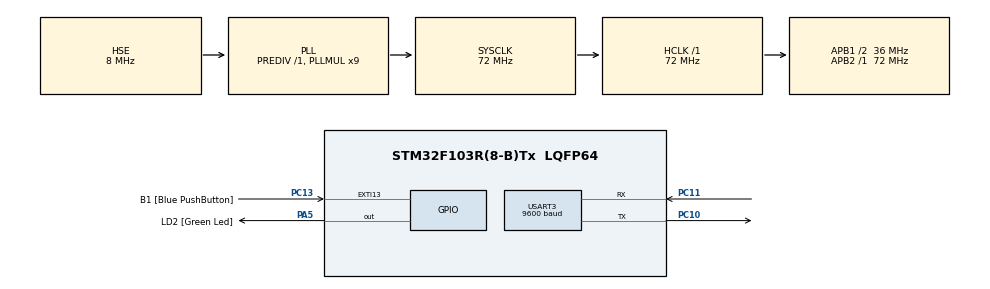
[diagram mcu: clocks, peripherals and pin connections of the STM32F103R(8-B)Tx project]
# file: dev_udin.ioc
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Dma.Request0=USART3_RX
Dma.Request1=USART3_TX
Dma.USART3_RX.0.Direction=DMA_PERIPH_TO_MEMORY
Dma.USART3_RX.0.Instance=DMA1_Channel3
Dma.USART3_RX.0.MemDataAlignment=DMA_MDATAALIGN_BYTE
Dma.USART3_RX.0.MemInc=DMA_MINC_ENABLE
Dma.USART3_RX.0.Mode=DMA_NORMAL
Dma.USART3_RX.0.PeriphDataAlignment=DMA_PDATAALIGN_BYTE
Dma.USART3_RX.0.PeriphInc=DMA_PINC_DISABLE
Dma.USART3_RX.0.Priority=DMA_PRIORITY_LOW
Dma.USART3_TX.1.Direction=DMA_MEMORY_TO_PERIPH
Dma.USART3_TX.1.Instance=DMA1_Channel2
Dma.USART3_TX.1.MemDataAlignment=DMA_MDATAALIGN_BYTE
Dma.USART3_TX.1.MemInc=DMA_MINC_ENABLE
Dma.USART3_TX.1.Mode=DMA_NORMAL
Dma.USART3_TX.1.PeriphDataAlignment=DMA_PDATAALIGN_BYTE
Dma.USART3_TX.1.PeriphInc=DMA_PINC_DISABLE
Dma.USART3_TX.1.Priority=DMA_PRIORITY_LOW
FREERTOS.Tasks01=defaultTask,0,128,StartDefaultTask,Default,NULL
Mcu.Family=STM32F1
Mcu.Name=STM32F103R(8-B)Tx
Mcu.Package=LQFP64
NVIC.DMA1_Channel2_IRQn=true\:5\:0\:false\:false\:true\:true
NVIC.DMA1_Channel3_IRQn=true\:5\:0\:false\:false\:true\:true
NVIC.EXTI15_10_IRQn=true\:5\:0\:false\:false\:true\:true
NVIC.PriorityGroup=NVIC_PRIORITYGROUP_4
NVIC.TIM2_IRQn=true\:0\:0\:false\:false\:true\:false
NVIC.TimeBase=TIM2_IRQn
NVIC.TimeBaseIP=TIM2
NVIC.USART3_IRQn=true\:0\:0\:false\:false\:true\:false
PA13.GPIO_Label=TMS
PA13.Mode=Serial_Wire
PA13.Signal=SYS_JTMS-SWDIO
PA14.GPIO_Label=TCK
PA14.Mode=Serial_Wire
PA14.Signal=SYS_JTCK-SWCLK
PA2.GPIO_Label=USART_TX
PA2.GPIO_Mode=GPIO_MODE_AF_PP
PA2.GPIO_PuPd=GPIO_NOPULL
PA2.GPIO_Speed=GPIO_SPEED_FREQ_LOW
PA2.Signal=USART2_TX
PA3.GPIO_Label=USART_RX
PA3.GPIO_Mode=GPIO_MODE_AF_PP
PA3.GPIO_PuPd=GPIO_NOPULL
PA3.GPIO_Speed=GPIO_SPEED_FREQ_LOW
PA3.Signal=USART2_RX
PA5.GPIO_Label=LD2 [Green Led]
PA5.GPIO_ModeDefaultOutputPP=GPIO_MODE_OUTPUT_PP
PA5.GPIO_PuPd=GPIO_NOPULL
PA5.GPIO_Speed=GPIO_SPEED_FREQ_LOW
PA5.Signal=GPIO_Output
PB3.GPIO_Label=SWO
PB3.Signal=SYS_JTDO-TRACESWO
PC10.Mode=Asynchronous
PC10.Signal=USART3_TX
PC11.Mode=Asynchronous
PC11.Signal=USART3_RX
PC13-TAMPER-RTC.GPIO_Label=B1 [Blue PushButton]
PC13-TAMPER-RTC.GPIO_ModeDefaultEXTI=GPIO_MODE_IT_FALLING
PC13-TAMPER-RTC.GPIO_PuPd=GPIO_NOPULL
PC13-TAMPER-RTC.Signal=GPXTI13
PC14-OSC32_IN.Mode=LSE-External-Oscillator
PC14-OSC32_IN.Signal=RCC_OSC32_IN
PC15-OSC32_OUT.Mode=LSE-External-Oscillator
PC15-OSC32_OUT.Signal=RCC_OSC32_OUT
PD0-OSC_IN.Mode=HSE-External-Oscillator
PD0-OSC_IN.Signal=RCC_OSC_IN
PD1-OSC_OUT.Mode=HSE-External-Oscillator
PD1-OSC_OUT.Signal=RCC_OSC_OUT
ProjectManager.HeapSize=0x200
ProjectManager.StackSize=0x400
ProjectManager.TargetToolchain=SW4STM32
RCC.AHBFreq_Value=72000000
RCC.APB1CLKDivider=RCC_HCLK_DIV2
RCC.APB1Freq_Value=36000000
RCC.APB1TimFreq_Value=72000000
RCC.APB2Freq_Value=72000000
RCC.APB2TimFreq_Value=72000000
RCC.HCLKFreq_Value=72000000
RCC.PLLMUL=RCC_PLL_MUL9
RCC.PLLSourceVirtual=RCC_PLLSOURCE_HSE
RCC.SYSCLKFreq_VALUE=72000000
RCC.SYSCLKSource=RCC_SYSCLKSOURCE_PLLCLK
RCC.USBFreq_Value=72000000
USART3.BaudRate=9600
USART3.VirtualMode=VM_ASYNC
VP_FREERTOS_VS_ENABLE.Mode=Enabled
VP_SYS_VS_tim2.Mode=TIM2
board=NUCLEO-F103RB

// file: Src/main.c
/**
  ******************************************************************************
  * File Name          : main.c
  * Description        : Main program body
  ******************************************************************************
  *
  * Copyright (c) 2017 STMicroelectronics International N.V.
  * All rights reserved.
  *
  * Redistribution and use in source and binary forms, with or without
  * modification, are permitted, provided that the following conditions are met:
  *
  * 1. Redistribution of source code must retain the above copyright notice,
  *    this list of conditions and the following disclaimer.
  * 2. Redistributions in binary form must reproduce the above copyright notice,
  *    this list of conditions and the following disclaimer in the documentation
  *    and/or other materials provided with the distribution.
  * 3. Neither the name of STMicroelectronics nor the names of other
  *    contributors to this software may be used to endorse or promote products
  *    derived from this software without specific written permission.
  * 4. This software, including modifications and/or derivative works of this
  *    software, must execute solely and exclusively on microcontroller or
  *    microprocessor devices manufactured by or for STMicroelectronics.
  * 5. Redistribution and use of this software other than as permitted under
  *    this license is void and will automatically terminate your rights under
  *    this license.
  *
  * THIS SOFTWARE IS PROVIDED BY STMICROELECTRONICS AND CONTRIBUTORS "AS IS"
  * AND ANY EXPRESS, IMPLIED OR STATUTORY WARRANTIES, INCLUDING, BUT NOT
  * LIMITED TO, THE IMPLIED WARRANTIES OF MERCHANTABILITY, FITNESS FOR A
  * PARTICULAR PURPOSE AND NON-INFRINGEMENT OF THIRD PARTY INTELLECTUAL PROPERTY
  * RIGHTS ARE DISCLAIMED TO THE FULLEST EXTENT PERMITTED BY LAW. IN NO EVENT
  * SHALL STMICROELECTRONICS OR CONTRIBUTORS BE LIABLE FOR ANY DIRECT, INDIRECT,
  * INCIDENTAL, SPECIAL, EXEMPLARY, OR CONSEQUENTIAL DAMAGES (INCLUDING, BUT NOT
  * LIMITED TO, PROCUREMENT OF SUBSTITUTE GOODS OR SERVICES; LOSS OF USE, DATA,
  * OR PROFITS; OR BUSINESS INTERRUPTION) HOWEVER CAUSED AND ON ANY THEORY OF
  * LIABILITY, WHETHER IN CONTRACT, STRICT LIABILITY, OR TORT (INCLUDING
  * NEGLIGENCE OR OTHERWISE) ARISING IN ANY WAY OUT OF THE USE OF THIS SOFTWARE,
  * EVEN IF ADVISED OF THE POSSIBILITY OF SUCH DAMAGE.
  *
  ******************************************************************************
  */
#include "main.h"
#include "stm32f1xx_hal.h"
#include "cmsis_os.h"

/* USER CODE BEGIN Includes */
#include "nn_console.h"
#include "nn_threads.h"
/* USER CODE END Includes */

UART_HandleTypeDef huart3;
DMA_HandleTypeDef hdma_usart3_rx;
DMA_HandleTypeDef hdma_usart3_tx;

osThreadId defaultTaskHandle;

/* USER CODE BEGIN PV */
/* Private variables ---------------------------------------------------------*/

/* USER CODE END PV */

void SystemClock_Config(void);
void Error_Handler(void);
static void MX_GPIO_Init(void);
static void MX_DMA_Init(void);
static void MX_USART3_UART_Init(void);
void StartDefaultTask(void const * argument);

/* USER CODE BEGIN PFP */
/* Private function prototypes -----------------------------------------------*/

/* USER CODE END PFP */

int main(void)
{

  /* MCU Configuration----------------------------------------------------------*/

  /* Reset of all peripherals, Initializes the Flash interface and the Systick. */
  HAL_Init();

  /* Configure the system clock */
  SystemClock_Config();

  /* Initialize all configured peripherals */
  MX_GPIO_Init();
  MX_DMA_Init();
  MX_USART3_UART_Init();

  /* Create the thread(s) */
  /* definition and creation of defaultTask */
  osThreadDef(defaultTask, StartDefaultTask, osPriorityNormal, 0, 128);
  defaultTaskHandle = osThreadCreate(osThread(defaultTask), NULL);

  /* USER CODE BEGIN RTOS_THREADS */
  /* add threads, ... */
  vStartConsole(configMINIMAL_STACK_SIZE, osPriorityNormal);
  /* USER CODE END RTOS_THREADS */

  /* USER CODE BEGIN RTOS_QUEUES */
  /* add queues, ... */
  startGenThread();
  /* USER CODE END RTOS_QUEUES */

  /* Start scheduler */
  osKernelStart();

  /* We should never get here as control is now taken by the scheduler */

  /* Infinite loop */
  /* USER CODE BEGIN WHILE */
  // User LED - LD2 connected to PA5 or PB13 depending on settings

  while (1)
  {
  /* USER CODE END WHILE */

  }

}

/** System Clock Configuration
*/
void SystemClock_Config(void)
{

  RCC_OscInitTypeDef RCC_OscInitStruct;
  RCC_ClkInitTypeDef RCC_ClkInitStruct;

    /**Initializes the CPU, AHB and APB busses clocks
    */
  RCC_OscInitStruct.OscillatorType = RCC_OSCILLATORTYPE_HSE;
  RCC_OscInitStruct.HSEState = RCC_HSE_ON;
  RCC_OscInitStruct.HSEPredivValue = RCC_HSE_PREDIV_DIV1;
  RCC_OscInitStruct.HSIState = RCC_HSI_ON;
  RCC_OscInitStruct.PLL.PLLState = RCC_PLL_ON;
  RCC_OscInitStruct.PLL.PLLSource = RCC_PLLSOURCE_HSE;
  RCC_OscInitStruct.PLL.PLLMUL = RCC_PLL_MUL9;
  if (HAL_RCC_OscConfig(&RCC_OscInitStruct) != HAL_OK)
  {
    Error_Handler();
  }

    /**Initializes the CPU, AHB and APB busses clocks
    */
  RCC_ClkInitStruct.ClockType = RCC_CLOCKTYPE_HCLK|RCC_CLOCKTYPE_SYSCLK
                              |RCC_CLOCKTYPE_PCLK1|RCC_CLOCKTYPE_PCLK2;
  RCC_ClkInitStruct.SYSCLKSource = RCC_SYSCLKSOURCE_PLLCLK;
  RCC_ClkInitStruct.AHBCLKDivider = RCC_SYSCLK_DIV1;
  RCC_ClkInitStruct.APB1CLKDivider = RCC_HCLK_DIV2;
  RCC_ClkInitStruct.APB2CLKDivider = RCC_HCLK_DIV1;

  if (HAL_RCC_ClockConfig(&RCC_ClkInitStruct, FLASH_LATENCY_2) != HAL_OK)
  {
    Error_Handler();
  }

    /**Configure the Systick interrupt time
    */
  HAL_SYSTICK_Config(HAL_RCC_GetHCLKFreq()/1000);

    /**Configure the Systick
    */
  HAL_SYSTICK_CLKSourceConfig(SYSTICK_CLKSOURCE_HCLK);

  /* SysTick_IRQn interrupt configuration */
  HAL_NVIC_SetPriority(SysTick_IRQn, 15, 0);
}

/* USART3 init function */
static void MX_USART3_UART_Init(void)
{

  huart3.Instance = USART3;
  huart3.Init.BaudRate = 9600;
  huart3.Init.WordLength = UART_WORDLENGTH_8B;
  huart3.Init.StopBits = UART_STOPBITS_1;
  huart3.Init.Parity = UART_PARITY_NONE;
  huart3.Init.Mode = UART_MODE_TX_RX;
  huart3.Init.HwFlowCtl = UART_HWCONTROL_NONE;
  huart3.Init.OverSampling = UART_OVERSAMPLING_16;
  if (HAL_UART_Init(&huart3) != HAL_OK)
  {
    Error_Handler();
  }

}

static void MX_DMA_Init(void)
{
  /* DMA controller clock enable */
  __HAL_RCC_DMA1_CLK_ENABLE();

  /* DMA interrupt init */
  /* DMA1_Channel2_IRQn interrupt configuration */
  HAL_NVIC_SetPriority(DMA1_Channel2_IRQn, 5, 0);
  HAL_NVIC_EnableIRQ(DMA1_Channel2_IRQn);
  /* DMA1_Channel3_IRQn interrupt configuration */
  HAL_NVIC_SetPriority(DMA1_Channel3_IRQn, 5, 0);
  HAL_NVIC_EnableIRQ(DMA1_Channel3_IRQn);

}

/** Configure pins as
        * Analog
        * Input
        * Output
        * EVENT_OUT
        * EXTI
     PA2   ------> USART2_TX
     PA3   ------> USART2_RX
*/
static void MX_GPIO_Init(void)
{

  GPIO_InitTypeDef GPIO_InitStruct;

  /* GPIO Ports Clock Enable */
  __HAL_RCC_GPIOC_CLK_ENABLE();
  __HAL_RCC_GPIOD_CLK_ENABLE();
  __HAL_RCC_GPIOA_CLK_ENABLE();
  __HAL_RCC_GPIOB_CLK_ENABLE();

  /*Configure GPIO pin Output Level */
  HAL_GPIO_WritePin(LD2_GPIO_Port, LD2_Pin, GPIO_PIN_RESET);

  /*Configure GPIO pin : B1_Pin */
  GPIO_InitStruct.Pin = B1_Pin;
  GPIO_InitStruct.Mode = GPIO_MODE_IT_FALLING;
  GPIO_InitStruct.Pull = GPIO_NOPULL;
  HAL_GPIO_Init(B1_GPIO_Port, &GPIO_InitStruct);

  /*Configure GPIO pins : USART_TX_Pin USART_RX_Pin */
  GPIO_InitStruct.Pin = USART_TX_Pin|USART_RX_Pin;
  GPIO_InitStruct.Mode = GPIO_MODE_AF_PP;
  GPIO_InitStruct.Speed = GPIO_SPEED_FREQ_LOW;
  HAL_GPIO_Init(GPIOA, &GPIO_InitStruct);

  /*Configure GPIO pin : LD2_Pin */
  GPIO_InitStruct.Pin = LD2_Pin;
  GPIO_InitStruct.Mode = GPIO_MODE_OUTPUT_PP;
  GPIO_InitStruct.Speed = GPIO_SPEED_FREQ_LOW;
  HAL_GPIO_Init(LD2_GPIO_Port, &GPIO_InitStruct);

  /* EXTI interrupt init*/
  HAL_NVIC_SetPriority(EXTI15_10_IRQn, 5, 0);
  HAL_NVIC_EnableIRQ(EXTI15_10_IRQn);

}

/* StartDefaultTask function */
void StartDefaultTask(void const * argument)
{

  for(;;)
  {
    osDelay(1);
  }
}

void HAL_TIM_PeriodElapsedCallback(TIM_HandleTypeDef *htim)
{
  if (htim->Instance == TIM2) {
    HAL_IncTick();
  }
}

void Error_Handler(void)
{
  while(1)
  {
  }
}

/************************ (C) COPYRIGHT STMicroelectronics *****END OF FILE****/
